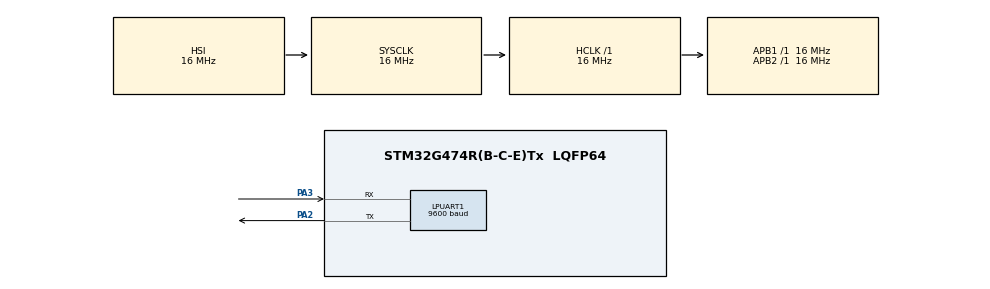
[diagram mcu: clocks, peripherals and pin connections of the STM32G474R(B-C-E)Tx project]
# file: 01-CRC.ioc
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LPUART1.BaudRate=9600
Mcu.Family=STM32G4
Mcu.Name=STM32G474R(B-C-E)Tx
Mcu.Package=LQFP64
NVIC.PriorityGroup=NVIC_PRIORITYGROUP_4
PA2.Mode=Asynchronous
PA2.Signal=LPUART1_TX
PA3.Mode=Asynchronous
PA3.Signal=LPUART1_RX
ProjectManager.HeapSize=0x200
ProjectManager.StackSize=0x400
ProjectManager.TargetToolchain=STM32CubeIDE
RCC.AHBFreq_Value=16000000
RCC.APB1Freq_Value=16000000
RCC.APB1TimFreq_Value=16000000
RCC.APB2Freq_Value=16000000
RCC.APB2TimFreq_Value=16000000
RCC.CortexFreq_Value=16000000
RCC.EXTERNAL_CLOCK_VALUE=12288000
RCC.HCLKFreq_Value=16000000
RCC.HSE_VALUE=8000000
RCC.HSI48_VALUE=48000000
RCC.HSI_VALUE=16000000
RCC.LSE_VALUE=32768
RCC.SYSCLKFreq_VALUE=16000000
RCC.USBFreq_Value=64000000
RCC.VCOOutputFreq_Value=128000000
VP_CRC_VS_CRC.Mode=CRC_Activate
VP_SYS_VS_DBSignals.Mode=DisableDeadBatterySignals
board=custom

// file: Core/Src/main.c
/* USER CODE BEGIN Header */
/**
  ******************************************************************************
  * @file           : main.c
  * @brief          : Main program body
  ******************************************************************************
  * @attention
  *
  * Copyright (c) 2025 STMicroelectronics.
  * All rights reserved.
  *
  * This software is licensed under terms that can be found in the LICENSE file
  * in the root directory of this software component.
  * If no LICENSE file comes with this software, it is provided AS-IS.
  *
  ******************************************************************************
  */
/* USER CODE END Header */
#include "main.h"

/* USER CODE BEGIN Includes */
#include <stdio.h>
/* USER CODE END Includes */

CRC_HandleTypeDef hcrc;

UART_HandleTypeDef hlpuart1;

void SystemClock_Config(void);
static void MX_GPIO_Init(void);
static void MX_LPUART1_UART_Init(void);
static void MX_CRC_Init(void);

/* USER CODE BEGIN 0 */
int __io_putchar(int ch)
{
	HAL_UART_Transmit(&hlpuart1, (const uint8_t *)&ch, 1, HAL_MAX_DELAY);
	return ch;
}
/* USER CODE END 0 */

int main(void)
{

  /* MCU Configuration--------------------------------------------------------*/

  /* Reset of all peripherals, Initializes the Flash interface and the Systick. */
  HAL_Init();

  /* Configure the system clock */
  SystemClock_Config();

  /* Initialize all configured peripherals */
  MX_GPIO_Init();
  MX_LPUART1_UART_Init();
  MX_CRC_Init();

  /* Infinite loop */
  /* USER CODE BEGIN WHILE */
  uint8_t buffer[] = {'1', '2'};
  while (1)
  {
	  HAL_Delay(1000);
	  uint32_t crc = HAL_CRC_Calculate(&hcrc, buffer, sizeof(buffer));
	  printf("CRC = %X\r\n", crc);
    /* USER CODE END WHILE */

  }
}

void SystemClock_Config(void)
{
  RCC_OscInitTypeDef RCC_OscInitStruct = {0};
  RCC_ClkInitTypeDef RCC_ClkInitStruct = {0};

  /** Configure the main internal regulator output voltage
  */
  HAL_PWREx_ControlVoltageScaling(PWR_REGULATOR_VOLTAGE_SCALE1);

  /** Initializes the RCC Oscillators according to the specified parameters
  * in the RCC_OscInitTypeDef structure.
  */
  RCC_OscInitStruct.OscillatorType = RCC_OSCILLATORTYPE_HSI;
  RCC_OscInitStruct.HSIState = RCC_HSI_ON;
  RCC_OscInitStruct.HSICalibrationValue = RCC_HSICALIBRATION_DEFAULT;
  RCC_OscInitStruct.PLL.PLLState = RCC_PLL_NONE;
  if (HAL_RCC_OscConfig(&RCC_OscInitStruct) != HAL_OK)
  {
    Error_Handler();
  }

  /** Initializes the CPU, AHB and APB buses clocks
  */
  RCC_ClkInitStruct.ClockType = RCC_CLOCKTYPE_HCLK|RCC_CLOCKTYPE_SYSCLK
                              |RCC_CLOCKTYPE_PCLK1|RCC_CLOCKTYPE_PCLK2;
  RCC_ClkInitStruct.SYSCLKSource = RCC_SYSCLKSOURCE_HSI;
  RCC_ClkInitStruct.AHBCLKDivider = RCC_SYSCLK_DIV1;
  RCC_ClkInitStruct.APB1CLKDivider = RCC_HCLK_DIV1;
  RCC_ClkInitStruct.APB2CLKDivider = RCC_HCLK_DIV1;

  if (HAL_RCC_ClockConfig(&RCC_ClkInitStruct, FLASH_LATENCY_0) != HAL_OK)
  {
    Error_Handler();
  }
}

static void MX_CRC_Init(void)
{

  hcrc.Instance = CRC;
  hcrc.Init.DefaultPolynomialUse = DEFAULT_POLYNOMIAL_ENABLE;
  hcrc.Init.DefaultInitValueUse = DEFAULT_INIT_VALUE_ENABLE;
  hcrc.Init.InputDataInversionMode = CRC_INPUTDATA_INVERSION_NONE;
  hcrc.Init.OutputDataInversionMode = CRC_OUTPUTDATA_INVERSION_DISABLE;
  hcrc.InputDataFormat = CRC_INPUTDATA_FORMAT_BYTES;
  if (HAL_CRC_Init(&hcrc) != HAL_OK)
  {
    Error_Handler();
  }

}

static void MX_LPUART1_UART_Init(void)
{

  hlpuart1.Instance = LPUART1;
  hlpuart1.Init.BaudRate = 9600;
  hlpuart1.Init.WordLength = UART_WORDLENGTH_8B;
  hlpuart1.Init.StopBits = UART_STOPBITS_1;
  hlpuart1.Init.Parity = UART_PARITY_NONE;
  hlpuart1.Init.Mode = UART_MODE_TX_RX;
  hlpuart1.Init.HwFlowCtl = UART_HWCONTROL_NONE;
  hlpuart1.Init.OneBitSampling = UART_ONE_BIT_SAMPLE_DISABLE;
  hlpuart1.Init.ClockPrescaler = UART_PRESCALER_DIV1;
  hlpuart1.AdvancedInit.AdvFeatureInit = UART_ADVFEATURE_NO_INIT;
  if (HAL_UART_Init(&hlpuart1) != HAL_OK)
  {
    Error_Handler();
  }
  if (HAL_UARTEx_SetTxFifoThreshold(&hlpuart1, UART_TXFIFO_THRESHOLD_1_8) != HAL_OK)
  {
    Error_Handler();
  }
  if (HAL_UARTEx_SetRxFifoThreshold(&hlpuart1, UART_RXFIFO_THRESHOLD_1_8) != HAL_OK)
  {
    Error_Handler();
  }
  if (HAL_UARTEx_DisableFifoMode(&hlpuart1) != HAL_OK)
  {
    Error_Handler();
  }

}

static void MX_GPIO_Init(void)
{

  /* GPIO Ports Clock Enable */
  __HAL_RCC_GPIOA_CLK_ENABLE();

}

void Error_Handler(void)
{
  __disable_irq();
  while (1)
  {
  }
}
